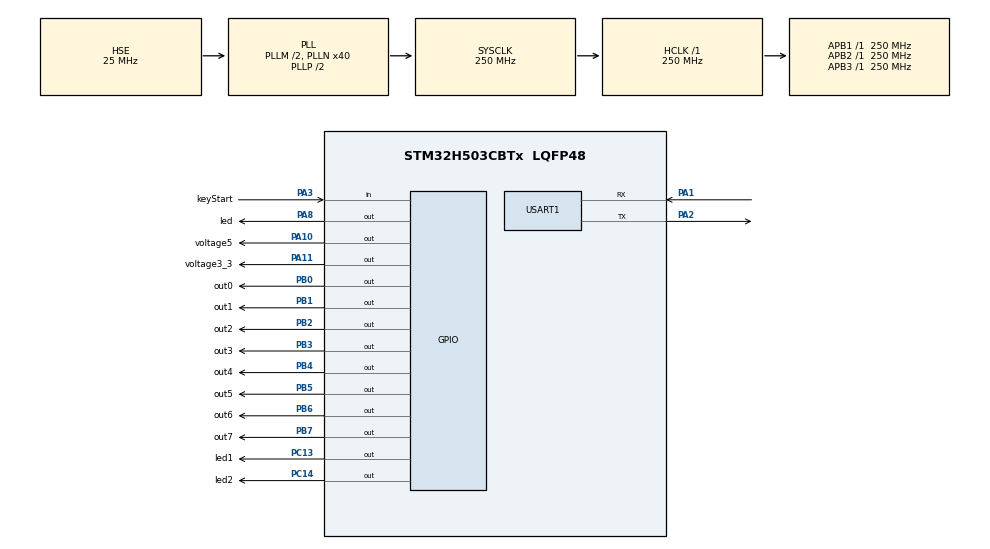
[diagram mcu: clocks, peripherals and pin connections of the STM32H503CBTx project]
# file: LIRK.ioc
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BOOTPATH.BootPathName=LEGACY
BOOTPATH.UserSelectedBootPath=LEGACY
GPDMA1.DESTDATAWIDTH_GPDMACH0=DMA_DEST_DATAWIDTH_WORD
GPDMA1.DIRECTION_GPDMACH0=DMA_MEMORY_TO_PERIPH
GPDMA1.IPHANDLE_GPDMACH0-SIMPLEREQUEST_GPDMACH0=__NULL
GPDMA1.PRIORITY_GPDMACH0=DMA_HIGH_PRIORITY
GPDMA1.REQUEST_GPDMACH0=GPDMA1_REQUEST_TIM2_UP
GPDMA1.SRCDATAWIDTH_GPDMACH0=DMA_SRC_DATAWIDTH_WORD
GPDMA1.SRCINC_GPDMACH0=DMA_SINC_INCREMENTED
GPDMA1.TRANSFERALLOCATEDPORTDEST_GPDMACH0=DMA_DEST_ALLOCATED_PORT0
GPDMA1.TRANSFERALLOCATEDPORTSRC_GPDMACH0=DMA_SRC_ALLOCATED_PORT1
GPDMA2.DESTDATAWIDTH_GPDMACH0=DMA_DEST_DATAWIDTH_WORD
GPDMA2.PRIORITY_GPDMACH0=DMA_LOW_PRIORITY_HIGH_WEIGHT
GPDMA2.SRCDATAWIDTH_GPDMACH0=DMA_SRC_DATAWIDTH_WORD
GPDMA2.SRCINC_GPDMACH0=DMA_SINC_INCREMENTED
GPDMA2.TRANSFERALLOCATEDPORTDEST_GPDMACH0=DMA_DEST_ALLOCATED_PORT1
GPDMA2.TRANSFERALLOCATEDPORTSRC_GPDMACH0=DMA_SRC_ALLOCATED_PORT1
GPDMA2.TRIGGERMODE_GPDMACH0=DMA_TRIGM_SINGLE_BURST_TRANSFER
GPDMA2.TRIGGERPOLARITY_GPDMACH0=DMA_TRIG_POLARITY_RISING
GPDMA2.TRIGGERSELECTION_GPDMACH0=GPDMA2_TRIGGER_TIM2_TRGO
Mcu.Family=STM32H5
Mcu.Name=STM32H503CBTx
Mcu.Package=LQFP48
NVIC.GPDMA1_Channel0_IRQn=true\:0\:0\:false\:false\:true\:false\:true\:true
NVIC.GPDMA2_Channel0_IRQn=true\:0\:0\:false\:false\:true\:true\:true\:true
NVIC.PriorityGroup=NVIC_PRIORITYGROUP_4
NVIC.USART1_IRQn=true\:0\:0\:false\:false\:true\:true\:true\:true
PA1.Mode=Asynchronous
PA1.Signal=USART1_RX
PA10.GPIO_Label=voltage5
PA10.Signal=GPIO_Output
PA11.GPIO_Label=voltage3_3
PA11.Signal=GPIO_Output
PA13(JTMS/SWDIO).Mode=Serial_Wire
PA13(JTMS/SWDIO).Signal=DEBUG_JTMS-SWDIO
PA14(JTCK/SWCLK).Mode=Serial_Wire
PA14(JTCK/SWCLK).Signal=DEBUG_JTCK-SWCLK
PA2.Mode=Asynchronous
PA2.Signal=USART1_TX
PA3.GPIO_Label=keyStart
PA3.GPIO_PuPd=GPIO_PULLUP
PA3.Signal=GPIO_Input
PA8.GPIO_Label=led
PA8.Signal=GPIO_Output
PB0.GPIO_Label=out0
PB0.GPIO_Speed=GPIO_SPEED_FREQ_VERY_HIGH
PB0.Signal=GPIO_Output
PB1.GPIO_Label=out1
PB1.GPIO_Speed=GPIO_SPEED_FREQ_VERY_HIGH
PB1.Signal=GPIO_Output
PB2.GPIO_Label=out2
PB2.GPIO_Speed=GPIO_SPEED_FREQ_VERY_HIGH
PB2.Signal=GPIO_Output
PB3(JTDO/TRACESWO).GPIO_Label=out3
PB3(JTDO/TRACESWO).GPIO_Speed=GPIO_SPEED_FREQ_VERY_HIGH
PB3(JTDO/TRACESWO).Signal=GPIO_Output
PB4(NJTRST).GPIO_Label=out4
PB4(NJTRST).Signal=GPIO_Output
PB5.GPIO_Label=out5
PB5.GPIO_Speed=GPIO_SPEED_FREQ_VERY_HIGH
PB5.Signal=GPIO_Output
PB6.GPIO_Label=out6
PB6.GPIO_Speed=GPIO_SPEED_FREQ_VERY_HIGH
PB6.Signal=GPIO_Output
PB7.GPIO_Label=out7
PB7.GPIO_Speed=GPIO_SPEED_FREQ_VERY_HIGH
PB7.Signal=GPIO_Output
PC13.GPIO_Label=led1
PC13.Signal=GPIO_Output
PC14-OSC32_IN(OSC32_IN).GPIO_Label=led2
PC14-OSC32_IN(OSC32_IN).Signal=GPIO_Output
PH0-OSC_IN(PH0).Mode=HSE-External-Oscillator
PH0-OSC_IN(PH0).Signal=RCC_OSC_IN
PH1-OSC_OUT(PH1).Mode=HSE-External-Oscillator
PH1-OSC_OUT(PH1).Signal=RCC_OSC_OUT
ProjectManager.HeapSize=0x200
ProjectManager.StackSize=0x400
ProjectManager.TargetToolchain=STM32CubeIDE
RCC.ADCFreq_Value=250000000
RCC.AHBFreq_Value=250000000
RCC.APB1Freq_Value=250000000
RCC.APB1TimFreq_Value=250000000
RCC.APB2Freq_Value=250000000
RCC.APB2TimFreq_Value=250000000
RCC.APB3Freq_Value=250000000
RCC.CSI_VALUE=4000000
RCC.CortexFreq_Value=250000000
RCC.EPOD_VALUE=25000000
RCC.HCLKFreq_Value=250000000
RCC.HSE_VALUE=25000000
RCC.HSI48_VALUE=48000000
RCC.HSI_VALUE=64000000
RCC.LSE_VALUE=32768
RCC.LSIRC_VALUE=32000
RCC.PLLFRACN=0
RCC.PLLM=2
RCC.PLLN=40
RCC.PLLSourceVirtual=RCC_PLL1_SOURCE_HSE
RCC.SYSCLKFreq_VALUE=250000000
RCC.SYSCLKSource=RCC_SYSCLKSOURCE_PLLCLK
RCC.USBFreq_Value=48000000
RCC.VCOOutputFreq_Value=500000000
TIM2.AutoReloadPreload=TIM_AUTORELOAD_PRELOAD_DISABLE
TIM2.PeriodNoDither=10000
TIM2.TIM_MasterOutputTrigger=TIM_TRGO_UPDATE
TIM2.TIM_MasterSlaveMode=TIM_MASTERSLAVEMODE_ENABLE
USART1.VirtualMode-Asynchronous=VM_ASYNC
VP_BOOTPATH_VS_BOOTPATH.Mode=BP_Activate
VP_CORTEX_M33_NS_VS_Hclk.Mode=Hclk_Mode
VP_GPDMA1_VS_GPDMACH0.Mode=SIMPLEREQUEST_GPDMACH0
VP_GPDMA2_VS_GPDMACH0.Mode=SIMPLEREQUEST_GPDMACH0
VP_ICACHE_VS_ICACHE.Mode=DirectMappedCache
VP_MEMORYMAP_VS_MEMORYMAP.Mode=CurAppReg
VP_PWR_VS_DBSignals.Mode=DisableDeadBatterySignals
VP_PWR_VS_LPOM.Mode=PowerOptimisation
VP_PWR_VS_SECSignals.Mode=Security/Privilege
VP_TIM2_VS_ClockSourceINT.Mode=Internal
board=custom

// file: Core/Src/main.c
/* USER CODE BEGIN Header */
/**
  ******************************************************************************
  * @file           : main.c
  * @brief          : Main program body
  ******************************************************************************
  * @attention
  *
  * Copyright (c) 2024 STMicroelectronics.
  * All rights reserved.
  *
  * This software is licensed under terms that can be found in the LICENSE file
  * in the root directory of this software component.
  * If no LICENSE file comes with this software, it is provided AS-IS.
  *
  ******************************************************************************
  */
/* USER CODE END Header */
#include "main.h"

DMA_HandleTypeDef handle_GPDMA2_Channel0;

TIM_HandleTypeDef htim2;
DMA_HandleTypeDef handle_GPDMA1_Channel0;

UART_HandleTypeDef huart1;

void SystemClock_Config(void);
static void MX_GPIO_Init(void);
static void MX_GPDMA1_Init(void);
static void MX_GPDMA2_Init(void);
static void MX_ICACHE_Init(void);
static void MX_USART1_UART_Init(void);
static void MX_TIM2_Init(void);

int main(void)
{

  /* MCU Configuration--------------------------------------------------------*/

  /* Reset of all peripherals, Initializes the Flash interface and the Systick. */
  HAL_Init();

  /* Configure the system clock */
  SystemClock_Config();

  /* Initialize all configured peripherals */
  MX_GPIO_Init();
  MX_GPDMA1_Init();
  MX_GPDMA2_Init();
  MX_ICACHE_Init();
  MX_USART1_UART_Init();
  MX_TIM2_Init();

  /* Infinite loop */
  /* USER CODE BEGIN WHILE */

	doWork();

  while (1)
  {
    /* USER CODE END WHILE */

    /* USER CODE BEGIN 3 */
	  work();
  }
  /* USER CODE END 3 */
}

void SystemClock_Config(void)
{
  RCC_OscInitTypeDef RCC_OscInitStruct = {0};
  RCC_ClkInitTypeDef RCC_ClkInitStruct = {0};

  /** Configure the main internal regulator output voltage
  */
  __HAL_PWR_VOLTAGESCALING_CONFIG(PWR_REGULATOR_VOLTAGE_SCALE0);

  while(!__HAL_PWR_GET_FLAG(PWR_FLAG_VOSRDY)) {}

  /** Initializes the RCC Oscillators according to the specified parameters
  * in the RCC_OscInitTypeDef structure.
  */
  RCC_OscInitStruct.OscillatorType = RCC_OSCILLATORTYPE_HSE;
  RCC_OscInitStruct.HSEState = RCC_HSE_ON;
  RCC_OscInitStruct.PLL.PLLState = RCC_PLL_ON;
  RCC_OscInitStruct.PLL.PLLSource = RCC_PLL1_SOURCE_HSE;
  RCC_OscInitStruct.PLL.PLLM = 2;
  RCC_OscInitStruct.PLL.PLLN = 40;
  RCC_OscInitStruct.PLL.PLLP = 2;
  RCC_OscInitStruct.PLL.PLLQ = 2;
  RCC_OscInitStruct.PLL.PLLR = 2;
  RCC_OscInitStruct.PLL.PLLRGE = RCC_PLL1_VCIRANGE_3;
  RCC_OscInitStruct.PLL.PLLVCOSEL = RCC_PLL1_VCORANGE_WIDE;
  RCC_OscInitStruct.PLL.PLLFRACN = 0;
  if (HAL_RCC_OscConfig(&RCC_OscInitStruct) != HAL_OK)
  {
    Error_Handler();
  }

  /** Initializes the CPU, AHB and APB buses clocks
  */
  RCC_ClkInitStruct.ClockType = RCC_CLOCKTYPE_HCLK|RCC_CLOCKTYPE_SYSCLK
                              |RCC_CLOCKTYPE_PCLK1|RCC_CLOCKTYPE_PCLK2
                              |RCC_CLOCKTYPE_PCLK3;
  RCC_ClkInitStruct.SYSCLKSource = RCC_SYSCLKSOURCE_PLLCLK;
  RCC_ClkInitStruct.AHBCLKDivider = RCC_SYSCLK_DIV1;
  RCC_ClkInitStruct.APB1CLKDivider = RCC_HCLK_DIV1;
  RCC_ClkInitStruct.APB2CLKDivider = RCC_HCLK_DIV1;
  RCC_ClkInitStruct.APB3CLKDivider = RCC_HCLK_DIV1;

  if (HAL_RCC_ClockConfig(&RCC_ClkInitStruct, FLASH_LATENCY_5) != HAL_OK)
  {
    Error_Handler();
  }

  /** Configure the programming delay
  */
  __HAL_FLASH_SET_PROGRAM_DELAY(FLASH_PROGRAMMING_DELAY_2);
}

static void MX_GPDMA1_Init(void)
{

  /* Peripheral clock enable */
  __HAL_RCC_GPDMA1_CLK_ENABLE();

  /* GPDMA1 interrupt Init */
    HAL_NVIC_SetPriority(GPDMA1_Channel0_IRQn, 0, 0);
    HAL_NVIC_EnableIRQ(GPDMA1_Channel0_IRQn);

}

static void MX_GPDMA2_Init(void)
{

  DMA_TriggerConfTypeDef TriggerConfig = {0};

  /* Peripheral clock enable */
  __HAL_RCC_GPDMA2_CLK_ENABLE();

  /* GPDMA2 interrupt Init */
    HAL_NVIC_SetPriority(GPDMA2_Channel0_IRQn, 0, 0);
    HAL_NVIC_EnableIRQ(GPDMA2_Channel0_IRQn);

  handle_GPDMA2_Channel0.Instance = GPDMA2_Channel0;
  handle_GPDMA2_Channel0.Init.Request = DMA_REQUEST_SW;
  handle_GPDMA2_Channel0.Init.BlkHWRequest = DMA_BREQ_SINGLE_BURST;
  handle_GPDMA2_Channel0.Init.Direction = DMA_MEMORY_TO_MEMORY;
  handle_GPDMA2_Channel0.Init.SrcInc = DMA_SINC_INCREMENTED;
  handle_GPDMA2_Channel0.Init.DestInc = DMA_DINC_FIXED;
  handle_GPDMA2_Channel0.Init.SrcDataWidth = DMA_SRC_DATAWIDTH_WORD;
  handle_GPDMA2_Channel0.Init.DestDataWidth = DMA_DEST_DATAWIDTH_WORD;
  handle_GPDMA2_Channel0.Init.Priority = DMA_LOW_PRIORITY_HIGH_WEIGHT;
  handle_GPDMA2_Channel0.Init.SrcBurstLength = 1;
  handle_GPDMA2_Channel0.Init.DestBurstLength = 1;
  handle_GPDMA2_Channel0.Init.TransferAllocatedPort = DMA_SRC_ALLOCATED_PORT1|DMA_DEST_ALLOCATED_PORT1;
  handle_GPDMA2_Channel0.Init.TransferEventMode = DMA_TCEM_BLOCK_TRANSFER;
  handle_GPDMA2_Channel0.Init.Mode = DMA_NORMAL;
  if (HAL_DMA_Init(&handle_GPDMA2_Channel0) != HAL_OK)
  {
    Error_Handler();
  }
  TriggerConfig.TriggerMode = DMA_TRIGM_SINGLE_BURST_TRANSFER;
  TriggerConfig.TriggerPolarity = DMA_TRIG_POLARITY_RISING;
  TriggerConfig.TriggerSelection = GPDMA2_TRIGGER_TIM2_TRGO;
  if (HAL_DMAEx_ConfigTrigger(&handle_GPDMA2_Channel0, &TriggerConfig) != HAL_OK)
  {
    Error_Handler();
  }
  if (HAL_DMA_ConfigChannelAttributes(&handle_GPDMA2_Channel0, DMA_CHANNEL_NPRIV) != HAL_OK)
  {
    Error_Handler();
  }

}

static void MX_ICACHE_Init(void)
{

  /** Enable instruction cache in 1-way (direct mapped cache)
  */
  if (HAL_ICACHE_ConfigAssociativityMode(ICACHE_1WAY) != HAL_OK)
  {
    Error_Handler();
  }
  if (HAL_ICACHE_Enable() != HAL_OK)
  {
    Error_Handler();
  }

}

static void MX_TIM2_Init(void)
{

  TIM_ClockConfigTypeDef sClockSourceConfig = {0};
  TIM_MasterConfigTypeDef sMasterConfig = {0};

  htim2.Instance = TIM2;
  htim2.Init.Prescaler = 0;
  htim2.Init.CounterMode = TIM_COUNTERMODE_UP;
  htim2.Init.Period = 10000;
  htim2.Init.ClockDivision = TIM_CLOCKDIVISION_DIV1;
  htim2.Init.AutoReloadPreload = TIM_AUTORELOAD_PRELOAD_DISABLE;
  if (HAL_TIM_Base_Init(&htim2) != HAL_OK)
  {
    Error_Handler();
  }
  sClockSourceConfig.ClockSource = TIM_CLOCKSOURCE_INTERNAL;
  if (HAL_TIM_ConfigClockSource(&htim2, &sClockSourceConfig) != HAL_OK)
  {
    Error_Handler();
  }
  sMasterConfig.MasterOutputTrigger = TIM_TRGO_UPDATE;
  sMasterConfig.MasterSlaveMode = TIM_MASTERSLAVEMODE_ENABLE;
  if (HAL_TIMEx_MasterConfigSynchronization(&htim2, &sMasterConfig) != HAL_OK)
  {
    Error_Handler();
  }

}

static void MX_USART1_UART_Init(void)
{

  huart1.Instance = USART1;
  huart1.Init.BaudRate = 115200;
  huart1.Init.WordLength = UART_WORDLENGTH_8B;
  huart1.Init.StopBits = UART_STOPBITS_1;
  huart1.Init.Parity = UART_PARITY_NONE;
  huart1.Init.Mode = UART_MODE_TX_RX;
  huart1.Init.HwFlowCtl = UART_HWCONTROL_NONE;
  huart1.Init.OverSampling = UART_OVERSAMPLING_16;
  huart1.Init.OneBitSampling = UART_ONE_BIT_SAMPLE_DISABLE;
  huart1.Init.ClockPrescaler = UART_PRESCALER_DIV1;
  huart1.AdvancedInit.AdvFeatureInit = UART_ADVFEATURE_NO_INIT;
  if (HAL_UART_Init(&huart1) != HAL_OK)
  {
    Error_Handler();
  }
  if (HAL_UARTEx_SetTxFifoThreshold(&huart1, UART_TXFIFO_THRESHOLD_1_8) != HAL_OK)
  {
    Error_Handler();
  }
  if (HAL_UARTEx_SetRxFifoThreshold(&huart1, UART_RXFIFO_THRESHOLD_1_8) != HAL_OK)
  {
    Error_Handler();
  }
  if (HAL_UARTEx_DisableFifoMode(&huart1) != HAL_OK)
  {
    Error_Handler();
  }

}

static void MX_GPIO_Init(void)
{
  GPIO_InitTypeDef GPIO_InitStruct = {0};

  /* GPIO Ports Clock Enable */
  __HAL_RCC_GPIOC_CLK_ENABLE();
  __HAL_RCC_GPIOH_CLK_ENABLE();
  __HAL_RCC_GPIOA_CLK_ENABLE();
  __HAL_RCC_GPIOB_CLK_ENABLE();

  /*Configure GPIO pin Output Level */
  HAL_GPIO_WritePin(GPIOC, led1_Pin|led2_Pin, GPIO_PIN_RESET);

  /*Configure GPIO pin Output Level */
  HAL_GPIO_WritePin(GPIOB, out0_Pin|out1_Pin|out2_Pin|out3_Pin
                          |out4_Pin|out5_Pin|out6_Pin|out7_Pin, GPIO_PIN_RESET);

  /*Configure GPIO pin Output Level */
  HAL_GPIO_WritePin(GPIOA, led_Pin|voltage5_Pin|voltage3_3_Pin, GPIO_PIN_RESET);

  /*Configure GPIO pins : led1_Pin led2_Pin */
  GPIO_InitStruct.Pin = led1_Pin|led2_Pin;
  GPIO_InitStruct.Mode = GPIO_MODE_OUTPUT_PP;
  GPIO_InitStruct.Pull = GPIO_NOPULL;
  GPIO_InitStruct.Speed = GPIO_SPEED_FREQ_LOW;
  HAL_GPIO_Init(GPIOC, &GPIO_InitStruct);

  /*Configure GPIO pin : keyStart_Pin */
  GPIO_InitStruct.Pin = keyStart_Pin;
  GPIO_InitStruct.Mode = GPIO_MODE_INPUT;
  GPIO_InitStruct.Pull = GPIO_PULLUP;
  HAL_GPIO_Init(keyStart_GPIO_Port, &GPIO_InitStruct);

  /*Configure GPIO pins : out0_Pin out1_Pin out2_Pin out3_Pin
                           out5_Pin out6_Pin out7_Pin */
  GPIO_InitStruct.Pin = out0_Pin|out1_Pin|out2_Pin|out3_Pin
                          |out5_Pin|out6_Pin|out7_Pin;
  GPIO_InitStruct.Mode = GPIO_MODE_OUTPUT_PP;
  GPIO_InitStruct.Pull = GPIO_NOPULL;
  GPIO_InitStruct.Speed = GPIO_SPEED_FREQ_VERY_HIGH;
  HAL_GPIO_Init(GPIOB, &GPIO_InitStruct);

  /*Configure GPIO pins : led_Pin voltage5_Pin voltage3_3_Pin */
  GPIO_InitStruct.Pin = led_Pin|voltage5_Pin|voltage3_3_Pin;
  GPIO_InitStruct.Mode = GPIO_MODE_OUTPUT_PP;
  GPIO_InitStruct.Pull = GPIO_NOPULL;
  GPIO_InitStruct.Speed = GPIO_SPEED_FREQ_LOW;
  HAL_GPIO_Init(GPIOA, &GPIO_InitStruct);

  /*Configure GPIO pin : out4_Pin */
  GPIO_InitStruct.Pin = out4_Pin;
  GPIO_InitStruct.Mode = GPIO_MODE_OUTPUT_PP;
  GPIO_InitStruct.Pull = GPIO_NOPULL;
  GPIO_InitStruct.Speed = GPIO_SPEED_FREQ_LOW;
  HAL_GPIO_Init(out4_GPIO_Port, &GPIO_InitStruct);

}

void Error_Handler(void)
{
  __disable_irq();
  while (1)
  {
  }
}
